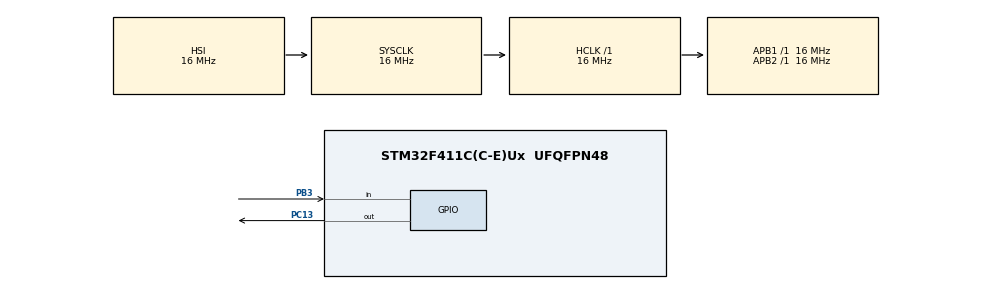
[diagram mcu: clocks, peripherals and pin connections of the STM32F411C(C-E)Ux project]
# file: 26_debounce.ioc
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Mcu.Family=STM32F4
Mcu.Name=STM32F411C(C-E)Ux
Mcu.Package=UFQFPN48
NVIC.PriorityGroup=NVIC_PRIORITYGROUP_4
PA13.Mode=Serial_Wire
PA13.Signal=SYS_JTMS-SWDIO
PA14.Mode=Serial_Wire
PA14.Signal=SYS_JTCK-SWCLK
PB3.GPIO_PuPd=GPIO_PULLUP
PB3.Signal=GPIO_Input
PC13-ANTI_TAMP.Signal=GPIO_Output
ProjectManager.HeapSize=0x200
ProjectManager.StackSize=0x400
ProjectManager.TargetToolchain=STM32CubeIDE
RCC.AHBFreq_Value=16000000
RCC.APB1Freq_Value=16000000
RCC.APB2Freq_Value=16000000
RCC.CortexFreq_Value=16000000
RCC.HSE_VALUE=25000000
RCC.HSI_VALUE=16000000
RCC.LSE_VALUE=32768
RCC.SYSCLKFreq_VALUE=16000000
RCC.VCOOutputFreq_Value=192000000
board=custom

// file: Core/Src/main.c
/* USER CODE BEGIN Header */
/**
 ******************************************************************************
 * @file           : main.c
 * @brief          : Main program body
 ******************************************************************************
 * @attention
 *
 * Copyright (c) 2026 STMicroelectronics.
 * All rights reserved.
 *
 * This software is licensed under terms that can be found in the LICENSE file
 * in the root directory of this software component.
 * If no LICENSE file comes with this software, it is provided AS-IS.
 *
 ******************************************************************************
 */
/* USER CODE END Header */
#include "main.h"

/* USER CODE BEGIN Includes */
#include "button_fsm/button_fsm.h"
/* USER CODE END Includes */

void SystemClock_Config(void);
static void MX_GPIO_Init(void);

/* USER CODE BEGIN 0 */

typedef struct
{
    uint32_t short_press;
    uint32_t long_press;
    uint32_t double_press;
    uint32_t stuck_press;
} press_counts_t;

press_counts_t counters;

static button_fsm_t s_button;
static bool s_led;

static void report_short(button_event_t ev, void* ctx)
{
    (void)ctx;
    s_led = !s_led;
    HAL_GPIO_WritePin(GPIOC, GPIO_PIN_13, s_led ? GPIO_PIN_SET : GPIO_PIN_RESET);
}

static void report_double(button_event_t ev, void* ctx)
{
    (void)ctx;
    s_led = false;
    HAL_GPIO_WritePin(GPIOC, GPIO_PIN_13, s_led ? GPIO_PIN_SET : GPIO_PIN_RESET);
}

static void report_long(button_event_t ev, void* ctx)
{
    (void)ctx;
    s_led = true;
    HAL_GPIO_WritePin(GPIOC, GPIO_PIN_13, s_led ? GPIO_PIN_SET : GPIO_PIN_RESET);
}

static void report_stuck(button_event_t ev, void* ctx)
{
    (void)ctx;
    s_led = false;
    HAL_GPIO_WritePin(GPIOC, GPIO_PIN_13, s_led ? GPIO_PIN_SET : GPIO_PIN_RESET);
}

void app_button_init(void)
{
    button_fsm_init(&s_button, (int64_t)HAL_GetTick() * 1000);
    button_fsm_register_callback(&s_button, BUTTON_EVENT_SHORT, &report_short);
    button_fsm_register_callback(&s_button, BUTTON_EVENT_DOUBLE, &report_double);
    button_fsm_register_callback(&s_button, BUTTON_EVENT_LONG, &report_long);
    button_fsm_register_callback(&s_button, BUTTON_EVENT_STUCK, &report_stuck);
}

void app_button_update(void)
{
    const bool pressed = HAL_GPIO_ReadPin(GPIOB, GPIO_PIN_3) == GPIO_PIN_RESET;
    button_fsm_poll(&s_button, pressed, (int64_t)HAL_GetTick() * 1000, (void*)&counters);
    HAL_Delay(10);
}
/* USER CODE END 0 */

int main(void)
{

    /* MCU Configuration--------------------------------------------------------*/

    /* Reset of all peripherals, Initializes the Flash interface and the Systick. */
    HAL_Init();

    /* Configure the system clock */
    SystemClock_Config();

    /* Initialize all configured peripherals */
    MX_GPIO_Init();
    /* USER CODE BEGIN 2 */
    app_button_init();
    /* USER CODE END 2 */

    /* Infinite loop */
    /* USER CODE BEGIN WHILE */
    while (1)
    {
        app_button_update();
        /* USER CODE END WHILE */

    }
}

void SystemClock_Config(void)
{
    RCC_OscInitTypeDef RCC_OscInitStruct = {0};
    RCC_ClkInitTypeDef RCC_ClkInitStruct = {0};

    /** Configure the main internal regulator output voltage
     */
    __HAL_RCC_PWR_CLK_ENABLE();
    __HAL_PWR_VOLTAGESCALING_CONFIG(PWR_REGULATOR_VOLTAGE_SCALE1);

    /** Initializes the RCC Oscillators according to the specified parameters
     * in the RCC_OscInitTypeDef structure.
     */
    RCC_OscInitStruct.OscillatorType = RCC_OSCILLATORTYPE_HSI;
    RCC_OscInitStruct.HSIState = RCC_HSI_ON;
    RCC_OscInitStruct.HSICalibrationValue = RCC_HSICALIBRATION_DEFAULT;
    RCC_OscInitStruct.PLL.PLLState = RCC_PLL_NONE;
    if (HAL_RCC_OscConfig(&RCC_OscInitStruct) != HAL_OK)
    {
        Error_Handler();
    }

    /** Initializes the CPU, AHB and APB buses clocks
     */
    RCC_ClkInitStruct.ClockType =
        RCC_CLOCKTYPE_HCLK | RCC_CLOCKTYPE_SYSCLK | RCC_CLOCKTYPE_PCLK1 | RCC_CLOCKTYPE_PCLK2;
    RCC_ClkInitStruct.SYSCLKSource = RCC_SYSCLKSOURCE_HSI;
    RCC_ClkInitStruct.AHBCLKDivider = RCC_SYSCLK_DIV1;
    RCC_ClkInitStruct.APB1CLKDivider = RCC_HCLK_DIV1;
    RCC_ClkInitStruct.APB2CLKDivider = RCC_HCLK_DIV1;

    if (HAL_RCC_ClockConfig(&RCC_ClkInitStruct, FLASH_LATENCY_0) != HAL_OK)
    {
        Error_Handler();
    }
}

static void MX_GPIO_Init(void)
{
    GPIO_InitTypeDef GPIO_InitStruct = {0};

    /* GPIO Ports Clock Enable */
    __HAL_RCC_GPIOC_CLK_ENABLE();
    __HAL_RCC_GPIOA_CLK_ENABLE();
    __HAL_RCC_GPIOB_CLK_ENABLE();

    /*Configure GPIO pin Output Level */
    HAL_GPIO_WritePin(GPIOC, GPIO_PIN_13, GPIO_PIN_RESET);

    /*Configure GPIO pin : PC13 */
    GPIO_InitStruct.Pin = GPIO_PIN_13;
    GPIO_InitStruct.Mode = GPIO_MODE_OUTPUT_PP;
    GPIO_InitStruct.Pull = GPIO_NOPULL;
    GPIO_InitStruct.Speed = GPIO_SPEED_FREQ_LOW;
    HAL_GPIO_Init(GPIOC, &GPIO_InitStruct);

    /*Configure GPIO pin : PB3 */
    GPIO_InitStruct.Pin = GPIO_PIN_3;
    GPIO_InitStruct.Mode = GPIO_MODE_INPUT;
    GPIO_InitStruct.Pull = GPIO_PULLUP;
    HAL_GPIO_Init(GPIOB, &GPIO_InitStruct);

}

void Error_Handler(void)
{
    __disable_irq();
    while (1)
    {
    }
}
#ifdef USE_FULL_ASSERT
/**
 * @brief  Reports the name of the source file and the source line number
 *         where the assert_param error has occurred.
 * @param  file: pointer to the source file name
 * @param  line: assert_param error line source number
 * @retval None
 */
void assert_failed(uint8_t* file, uint32_t line)
{
    /* USER CODE BEGIN 6 */
    /* User can add his own implementation to report the file name and line number,
       printf("Wrong parameters value: file %s on line %d\r\n", file, line) */
    /* USER CODE END 6 */
}
#endif /* USE_FULL_ASSERT */
